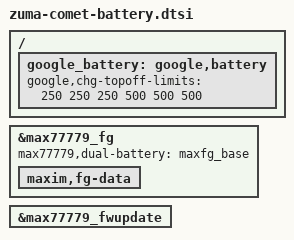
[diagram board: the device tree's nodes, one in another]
// SPDX-License-Identifier: GPL-2.0-only
/*
 * Battery device tree entries specific to comet
 *
 * Copyright 2023 Google LLC
 *
 */

#include "google-dts-base/zuma-dual-battery-common.dtsi"
#include "google-dts-base/zuma-max777xx_fwupdate.dtsi"

/ {
	fragment@battery {
		target-path = "/";
		__overlay__ {

			google_battery: google,battery {
				google,chg-topoff-limits = <250 250 250 500 500 500>;
			};
		};
	};
};

&max77779_fg {
	max77779,dual-battery = "maxfg_base";
	maxim,fg-data {
		#include "zuma-comet-battery-data.dtsi"
	};
};

&max77779_fwupdate {
	status = "okay";
};

